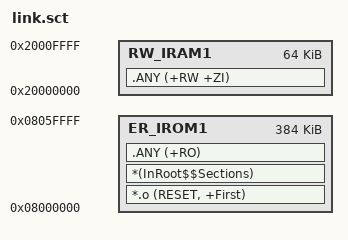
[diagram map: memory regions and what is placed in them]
; *************************************************************
; *** Scatter-Loading Description File generated by uVision ***
; *************************************************************

LR_IROM1 0x08000000 0x00060000  {    ; load region size_region (384KB)
  ER_IROM1 0x08000000 0x00060000  {  ; load address = execution address (384KB)
   *.o (RESET, +First)
   *(InRoot$$Sections)
   .ANY (+RO)
  }
  RW_IRAM1 0x20000000 0x00010000  {  ; RW data (64KB)
   .ANY (+RW +ZI)
  }
}

